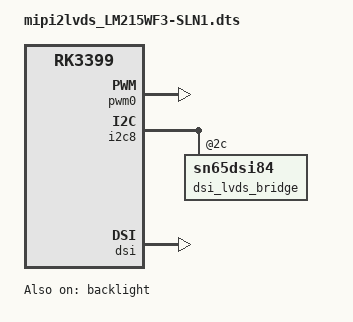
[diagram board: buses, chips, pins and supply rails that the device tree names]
/dts-v1/;
/plugin/;
/ {
	compatible = "rockchip,rk3399";

	fragment@0 {
		target = <&pwm0>;
		__overlay__ {
			status = "okay";
		};
	};
	fragment@1 {
		target = <&backlight>;
		__overlay__ {
			status = "okay";
			pwms = <&pwm0 0 4000000 0>;
                        minimal-brightness-level = <1>;
                        brightness-levels = <
				0    255 254 253 252 251 250 249
				248 247 246 245 244 243 242 241
				240 239 238 237 236 235 234 233
				231 231 230 229 228 227 226 225
				224 223 222 221 220 219 218 217
				216 215 214 213 212 211 210 209
				208 207 206 205 204 203 202 201
				200 199 198 197 196 195 194 193
				192 191 190 189 188 187 186 185
				184 183 182 181 180 179 178 177
				176 175 174 173 172 171 170 169
				168 167 166 165 164 163 162 161
				160 159 158 157 156 155 154 153
				152 151 150 149 148 147 146 145
				144 143 142 141 140 139 138 137
				136 135 134 133 132 131 130 129
				128 127 126 125 124 123 122 121
				120 119 118 117 116 115 114 113
				112 111 110 109 108 107 106 105
				104 103 102 101 100 99 98 97
				96 95 94 93 92 91 90 89
				88 87 86 85 84 83 82 81
				80 79 78 77 76 75 74 73
				72 71 70 69 68 67 66 65
				64 63 62 61 60 59 58 57
				56 55 54 53 52 51 50 49
				48 47 46 45 44 43 42 41
				40 39 38 37 36 35 34 33
				32 31 30 29 28 27 26 25
				24 23 22 21 20 19 18 17
				16 15 14 13 12 11 10 9
				8 7 6 5 4 3 2 1
		           >;
		};
	};
	fragment@2 {
		target = <&i2c8>;
		__overlay__ {
			status = "okay";
			dsi_lvds_bridge: sn65dsi84@2c {
				status = "okay";
				lvds-clk-rate = <72000000>;
				lvds-format = <2>;
				lvds-bpp = <24>;
				dsi-lanes = <4>;
				sync_delay = <33>;
				dual-link;

				t1=<0>;
				t2=<1>;
				t3=<500>;
				t4=<200>;
				t5=<1>;
				t6=<0>;
				t7=<1000>;
			};
		};
	};
	fragment@3 {
		target = <&dsi>;
		__overlay__ {
			status = "okay";
			panel@0 {
				backlight = <&backlight>;

				width-mm = <476>;
				height-mm = <267>;
				bpc=<8>;
				bus-format = <0x100a>;//<MEDIA_BUS_FMT_RGB888_1X24>;
				dsi,flags = <0x3>;
				dsi,format = <0>;//MIPI_DSI_FMT_RGB888:
				dsi,lanes = <4>;

				display-timings {
					native-mode = <&timing84>;

					timing84: timing84  {
						clock-frequency = <144000000>;
						hactive = <1920>;
						vactive = <1080>;
						hfront-porch = <96>;
						hback-porch = <96>;
						hsync-len = <64>;
						vfront-porch = <8>;
						vsync-len = <4>;
						vback-porch = <8>;
						hsync-active = <0>;
						vsync-active = <0>;
						de-active = <1>;
						pixelclk-active = <0>;
					};
				};
			};
		};
	};
       fragment@4 {
		target = <&pinctrl>;
		__overlay__ {
			pinctrl-0 = <&gpio_init2>;
			gpio_init_config {
				gpio_init2: gpio_init2 {
					rockchip,pins =
						<2 19 0 &pcfg_pull_none>;
				};
			};
		};
	};
};
